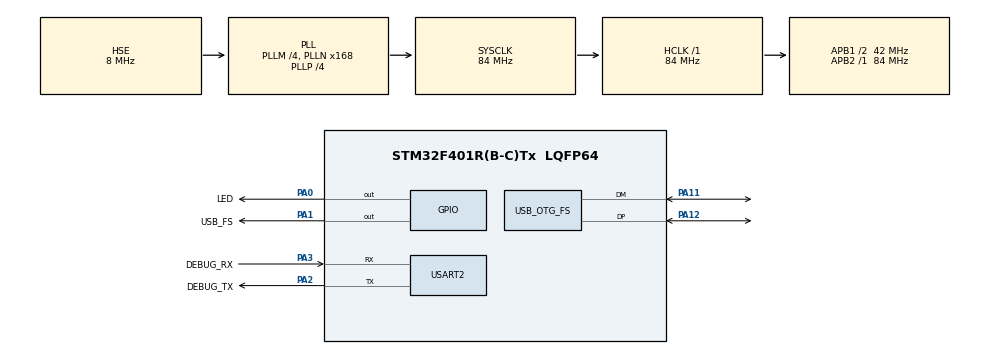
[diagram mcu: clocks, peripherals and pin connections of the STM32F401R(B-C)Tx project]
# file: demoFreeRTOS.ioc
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FREERTOS.Queues01=taskQueue,16,uint16_t,0,Dynamic,NULL,NULL
FREERTOS.Tasks01=mainTaskName,0,128,mainTask,Default,NULL,Dynamic,NULL,NULL;secondTaskName,-3,128,secondTask,Default,NULL,Dynamic,NULL,NULL
Mcu.Family=STM32F4
Mcu.Name=STM32F401R(B-C)Tx
Mcu.Package=LQFP64
NVIC.OTG_FS_IRQn=true\:0\:0\:false\:false\:true\:false\:true\:true
NVIC.PriorityGroup=NVIC_PRIORITYGROUP_4
NVIC.TIM1_UP_TIM10_IRQn=true\:0\:0\:false\:false\:true\:false\:true\:true
NVIC.TimeBase=TIM1_UP_TIM10_IRQn
NVIC.TimeBaseIP=TIM1
PA0-WKUP.GPIO_Label=LED
PA0-WKUP.Signal=GPIO_Output
PA1.GPIO_Label=USB_FS
PA1.Signal=GPIO_Output
PA11.Mode=Host_Only
PA11.Signal=USB_OTG_FS_DM
PA12.Mode=Host_Only
PA12.Signal=USB_OTG_FS_DP
PA2.GPIO_Label=DEBUG_TX
PA2.Mode=Asynchronous
PA2.Signal=USART2_TX
PA3.GPIO_Label=DEBUG_RX
PA3.Mode=Asynchronous
PA3.Signal=USART2_RX
PH0\ -\ OSC_IN.Mode=HSE-External-Oscillator
PH0\ -\ OSC_IN.Signal=RCC_OSC_IN
PH1\ -\ OSC_OUT.Mode=HSE-External-Oscillator
PH1\ -\ OSC_OUT.Signal=RCC_OSC_OUT
ProjectManager.HeapSize=0x200
ProjectManager.StackSize=0x400
ProjectManager.TargetToolchain=Makefile
RCC.48MHZClocksFreq_Value=48000000
RCC.AHBFreq_Value=84000000
RCC.APB1CLKDivider=RCC_HCLK_DIV2
RCC.APB1Freq_Value=42000000
RCC.APB1TimFreq_Value=84000000
RCC.APB2Freq_Value=84000000
RCC.APB2TimFreq_Value=84000000
RCC.CortexFreq_Value=84000000
RCC.HCLKFreq_Value=84000000
RCC.HSE_VALUE=8000000
RCC.HSI_VALUE=16000000
RCC.LSE_VALUE=32768
RCC.PLLM=4
RCC.PLLN=168
RCC.PLLP=RCC_PLLP_DIV4
RCC.PLLQ=7
RCC.SYSCLKFreq_VALUE=84000000
RCC.SYSCLKSource=RCC_SYSCLKSOURCE_PLLCLK
RCC.VCOOutputFreq_Value=336000000
USART2.VirtualMode=VM_ASYNC
USB_HOST.BSP.number=1
USB_HOST.USBH_HandleTypeDef=hUsbHostFS
USB_HOST.VirtualModeFS=Hid
USB_HOST0.BSP.STBoard=false
USB_HOST0.BSP.api=Unknown
USB_HOST0.BSP.instance=PA1
USB_HOST0.BSP.ip=GPIO
USB_HOST0.BSP.mode=Output
USB_HOST0.BSP.name=Drive_VBUS_FS
USB_HOST0.BSP.solution=PA1
USB_OTG_FS.VirtualMode=Host_Only
USB_OTG_FS.phy_itface=HCD_PHY_EMBEDDED
VP_FREERTOS_VS_ENABLE.Mode=Enabled
VP_SYS_VS_tim1.Mode=TIM1
VP_USB_HOST_VS_USB_HOST_HID_FS.Mode=HID_FS
board=custom

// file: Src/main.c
/**
  ******************************************************************************
  * @file           : main.c
  * @brief          : Main program body
  ******************************************************************************
  * This notice applies to any and all portions of this file
  * that are not between comment pairs USER CODE BEGIN and
  * USER CODE END. Other portions of this file, whether
  * inserted by the user or by software development tools
  * are owned by their respective copyright owners.
  *
  * Copyright (c) 2025 STMicroelectronics International N.V.
  * All rights reserved.
  *
  * Redistribution and use in source and binary forms, with or without
  * modification, are permitted, provided that the following conditions are met:
  *
  * 1. Redistribution of source code must retain the above copyright notice,
  *    this list of conditions and the following disclaimer.
  * 2. Redistributions in binary form must reproduce the above copyright notice,
  *    this list of conditions and the following disclaimer in the documentation
  *    and/or other materials provided with the distribution.
  * 3. Neither the name of STMicroelectronics nor the names of other
  *    contributors to this software may be used to endorse or promote products
  *    derived from this software without specific written permission.
  * 4. This software, including modifications and/or derivative works of this
  *    software, must execute solely and exclusively on microcontroller or
  *    microprocessor devices manufactured by or for STMicroelectronics.
  * 5. Redistribution and use of this software other than as permitted under
  *    this license is void and will automatically terminate your rights under
  *    this license.
  *
  * THIS SOFTWARE IS PROVIDED BY STMICROELECTRONICS AND CONTRIBUTORS "AS IS"
  * AND ANY EXPRESS, IMPLIED OR STATUTORY WARRANTIES, INCLUDING, BUT NOT
  * LIMITED TO, THE IMPLIED WARRANTIES OF MERCHANTABILITY, FITNESS FOR A
  * PARTICULAR PURPOSE AND NON-INFRINGEMENT OF THIRD PARTY INTELLECTUAL PROPERTY
  * RIGHTS ARE DISCLAIMED TO THE FULLEST EXTENT PERMITTED BY LAW. IN NO EVENT
  * SHALL STMICROELECTRONICS OR CONTRIBUTORS BE LIABLE FOR ANY DIRECT, INDIRECT,
  * INCIDENTAL, SPECIAL, EXEMPLARY, OR CONSEQUENTIAL DAMAGES (INCLUDING, BUT NOT
  * LIMITED TO, PROCUREMENT OF SUBSTITUTE GOODS OR SERVICES; LOSS OF USE, DATA,
  * OR PROFITS; OR BUSINESS INTERRUPTION) HOWEVER CAUSED AND ON ANY THEORY OF
  * LIABILITY, WHETHER IN CONTRACT, STRICT LIABILITY, OR TORT (INCLUDING
  * NEGLIGENCE OR OTHERWISE) ARISING IN ANY WAY OUT OF THE USE OF THIS SOFTWARE,
  * EVEN IF ADVISED OF THE POSSIBILITY OF SUCH DAMAGE.
  *
  ******************************************************************************
  */
#include "main.h"
#include "stm32f4xx_hal.h"
#include "cmsis_os.h"
#include "usb_host.h"
#include <errno.h>
#include <stm32f4xx_hal.h> // per HAL_StatusTypeDef
#include <sys/unistd.h> // STDOUT_FILENO, STDERR_FILENO

typedef enum {
	SYSCALL_NOTREADY,
	SYSCALL_READY,
} t_syscall_status;

static t_syscall_status uart_initialize = SYSCALL_NOTREADY;
static UART_HandleTypeDef *uart = NULL;

UART_HandleTypeDef huart2;

osThreadId mainTaskNameHandle;
osThreadId secondTaskNameHandle;
osMessageQId taskQueueHandle;

/* USER CODE BEGIN PV */
/* Private variables ---------------------------------------------------------*/

/* USER CODE END PV */

void SystemClock_Config(void);
static void MX_GPIO_Init(void);
static void MX_USART2_UART_Init(void);
void mainTask(void const * argument);
void secondTask(void const * argument);

/* USER CODE BEGIN PFP */
/* Private function prototypes -----------------------------------------------*/

/* USER CODE END PFP */

int _write(int file, char *data, int len)
{
	HAL_StatusTypeDef status = HAL_OK - 1;

	if ((file != STDOUT_FILENO) && (file != STDERR_FILENO))
	{
		errno = EBADF;
		return -1;
	}

	if (uart_initialize == SYSCALL_READY)
	{
		if (uart != NULL)
		{
			// arbitrary timeout 1000
			status = HAL_UART_Transmit(uart, (uint8_t*)data, len, 1000);
		}
	}

	// return # of bytes written - as best we can tell
	return (status == HAL_OK ? len : 0);
}

int main(void)
{

  /* MCU Configuration----------------------------------------------------------*/

  /* Reset of all peripherals, Initializes the Flash interface and the Systick. */
  HAL_Init();

  /* Configure the system clock */
  SystemClock_Config();

  /* Initialize all configured peripherals */
  MX_GPIO_Init();
  MX_USART2_UART_Init();
  uart_initialize = SYSCALL_READY;
  uart = &huart2;

  printf("MAIN\n\r");
  #if 1
  /* Create the thread(s) */
  /* definition and creation of mainTaskName */
  osThreadDef(mainTaskName, mainTask, osPriorityNormal, 0, 128);
  mainTaskNameHandle = osThreadCreate(osThread(mainTaskName), NULL);

  /* definition and creation of secondTaskName */
  osThreadDef(secondTaskName, secondTask, osPriorityIdle, 0, 128);
  secondTaskNameHandle = osThreadCreate(osThread(secondTaskName), NULL);

  /* Create the queue(s) */
  /* definition and creation of taskQueue */
/* what about the sizeof here??? cd native code */
  osMessageQDef(taskQueue, 16, uint16_t);
  taskQueueHandle = osMessageCreate(osMessageQ(taskQueue), NULL);

  /* Start scheduler */
  osKernelStart();

  /* We should never get here as control is now taken by the scheduler */
#endif
  /* Infinite loop */
  while (1)
  {

  }

}

void SystemClock_Config(void)
{

  RCC_OscInitTypeDef RCC_OscInitStruct;
  RCC_ClkInitTypeDef RCC_ClkInitStruct;

    /**Configure the main internal regulator output voltage
    */
  __HAL_RCC_PWR_CLK_ENABLE();

  __HAL_PWR_VOLTAGESCALING_CONFIG(PWR_REGULATOR_VOLTAGE_SCALE2);

    /**Initializes the CPU, AHB and APB busses clocks
    */
  RCC_OscInitStruct.OscillatorType = RCC_OSCILLATORTYPE_HSE;
  RCC_OscInitStruct.HSEState = RCC_HSE_ON;
  RCC_OscInitStruct.PLL.PLLState = RCC_PLL_ON;
  RCC_OscInitStruct.PLL.PLLSource = RCC_PLLSOURCE_HSE;
  RCC_OscInitStruct.PLL.PLLM = 4;
  RCC_OscInitStruct.PLL.PLLN = 168;
  RCC_OscInitStruct.PLL.PLLP = RCC_PLLP_DIV4;
  RCC_OscInitStruct.PLL.PLLQ = 7;
  if (HAL_RCC_OscConfig(&RCC_OscInitStruct) != HAL_OK)
  {
    _Error_Handler(__FILE__, __LINE__);
  }

    /**Initializes the CPU, AHB and APB busses clocks
    */
  RCC_ClkInitStruct.ClockType = RCC_CLOCKTYPE_HCLK|RCC_CLOCKTYPE_SYSCLK
                              |RCC_CLOCKTYPE_PCLK1|RCC_CLOCKTYPE_PCLK2;
  RCC_ClkInitStruct.SYSCLKSource = RCC_SYSCLKSOURCE_PLLCLK;
  RCC_ClkInitStruct.AHBCLKDivider = RCC_SYSCLK_DIV1;
  RCC_ClkInitStruct.APB1CLKDivider = RCC_HCLK_DIV2;
  RCC_ClkInitStruct.APB2CLKDivider = RCC_HCLK_DIV1;

  if (HAL_RCC_ClockConfig(&RCC_ClkInitStruct, FLASH_LATENCY_2) != HAL_OK)
  {
    _Error_Handler(__FILE__, __LINE__);
  }

    /**Configure the Systick interrupt time
    */
  HAL_SYSTICK_Config(HAL_RCC_GetHCLKFreq()/1000);

    /**Configure the Systick
    */
  HAL_SYSTICK_CLKSourceConfig(SYSTICK_CLKSOURCE_HCLK);

  /* SysTick_IRQn interrupt configuration */
  HAL_NVIC_SetPriority(SysTick_IRQn, 15, 0);
}

/* USART2 init function */
static void MX_USART2_UART_Init(void)
{

  huart2.Instance = USART2;
  huart2.Init.BaudRate = 115200;
  huart2.Init.WordLength = UART_WORDLENGTH_8B;
  huart2.Init.StopBits = UART_STOPBITS_1;
  huart2.Init.Parity = UART_PARITY_NONE;
  huart2.Init.Mode = UART_MODE_TX_RX;
  huart2.Init.HwFlowCtl = UART_HWCONTROL_NONE;
  huart2.Init.OverSampling = UART_OVERSAMPLING_16;
  if (HAL_UART_Init(&huart2) != HAL_OK)
  {
    _Error_Handler(__FILE__, __LINE__);
  }

}

/** Configure pins as
        * Analog
        * Input
        * Output
        * EVENT_OUT
        * EXTI
*/
static void MX_GPIO_Init(void)
{

  GPIO_InitTypeDef GPIO_InitStruct;

  /* GPIO Ports Clock Enable */
  __HAL_RCC_GPIOH_CLK_ENABLE();
  __HAL_RCC_GPIOA_CLK_ENABLE();

  /*Configure GPIO pin Output Level */
  HAL_GPIO_WritePin(GPIOA, LED_Pin|USB_FS_Pin, GPIO_PIN_RESET);

  /*Configure GPIO pins : LED_Pin USB_FS_Pin */
  GPIO_InitStruct.Pin = LED_Pin|USB_FS_Pin;
  GPIO_InitStruct.Mode = GPIO_MODE_OUTPUT_PP;
  GPIO_InitStruct.Pull = GPIO_NOPULL;
  GPIO_InitStruct.Speed = GPIO_SPEED_FREQ_LOW;
  HAL_GPIO_Init(GPIOA, &GPIO_InitStruct);

}

static void led_light(int state)
{
	int tpval = GPIO_PIN_RESET;

	if (!!state)
	{
		tpval = GPIO_PIN_SET;
	}
	else
	{
		tpval = GPIO_PIN_RESET;
	}
	HAL_GPIO_WritePin(LED_GPIO_Port, LED_Pin, tpval);
}

static void led_toggle(void)
{
	static int tpval = 0;
	if (tpval == 0)
	{
		tpval = 1;
	}
	else
	{
		tpval = 0;
	}
	led_light(tpval);
}

void mainTask(void const * argument)
{
  /* init code for USB_HOST */
  MX_USB_HOST_Init();

  /* USER CODE BEGIN 5 */
  /* Infinite loop */
  for(;;)
  {
	  printf("FROM MAIN TASK\n\r");
	HAL_GPIO_WritePin(LED_GPIO_Port, LED_Pin, 0);

    osDelay(100);
  }
  /* USER CODE END 5 */
}

void secondTask(void const * argument)
{
  /* USER CODE BEGIN secondTask */
  /* Infinite loop */
  for(;;)
  {
	  printf("\t\t\tFROM SECOND TASK\n\r");
	  	HAL_GPIO_WritePin(LED_GPIO_Port, LED_Pin, 1);

    osDelay(200);
  }
  /* USER CODE END secondTask */
}

void HAL_TIM_PeriodElapsedCallback(TIM_HandleTypeDef *htim)
{
  if (htim->Instance == TIM1) {
    HAL_IncTick();
  }
}

void _Error_Handler(char *file, int line)
{
  while(1)
  {
  }
}

/************************ (C) COPYRIGHT STMicroelectronics *****END OF FILE****/
